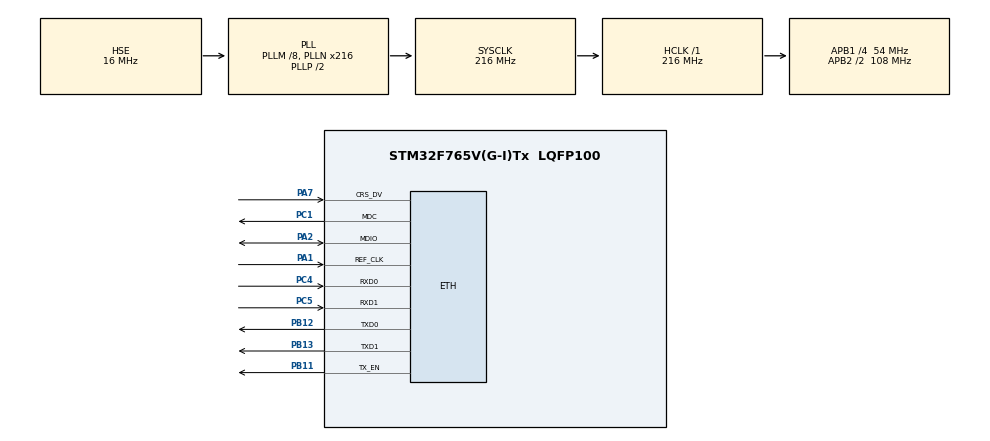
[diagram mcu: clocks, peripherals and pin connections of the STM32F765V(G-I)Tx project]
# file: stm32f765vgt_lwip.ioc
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ETH.ETH_RX_DESC_CNT=0
ETH.ETH_TX_DESC_CNT=0
ETH.MediaInterface=HAL_ETH_RMII_MODE
ETH.RxMode=ETH_RXINTERRUPT_MODE
FREERTOS.Tasks01=defaultTask,0,128,StartDefaultTask,Default,NULL,Dynamic,NULL,NULL
FREERTOS.configUSE_NEWLIB_REENTRANT=1
Mcu.Family=STM32F7
Mcu.Name=STM32F765V(G-I)Tx
Mcu.Package=LQFP100
NVIC.ETH_IRQn=true\:5\:0\:false\:false\:true\:true\:false\:true\:true
NVIC.PriorityGroup=NVIC_PRIORITYGROUP_4
NVIC.TIM8_BRK_TIM12_IRQn=true\:15\:0\:false\:false\:true\:false\:false\:true\:true
NVIC.TimeBase=TIM8_BRK_TIM12_IRQn
NVIC.TimeBaseIP=TIM12
PA1.Mode=RMII
PA1.Signal=ETH_REF_CLK
PA13.Mode=Serial_Wire
PA13.Signal=SYS_JTMS-SWDIO
PA14.Mode=Serial_Wire
PA14.Signal=SYS_JTCK-SWCLK
PA2.Mode=RMII
PA2.Signal=ETH_MDIO
PA7.Mode=RMII
PA7.Signal=ETH_CRS_DV
PB11.Mode=RMII
PB11.Signal=ETH_TX_EN
PB12.Mode=RMII
PB12.Signal=ETH_TXD0
PB13.Mode=RMII
PB13.Signal=ETH_TXD1
PC1.Mode=RMII
PC1.Signal=ETH_MDC
PC4.Mode=RMII
PC4.Signal=ETH_RXD0
PC5.Mode=RMII
PC5.Signal=ETH_RXD1
PH0/OSC_IN.Mode=HSE-External-Oscillator
PH0/OSC_IN.Signal=RCC_OSC_IN
PH1/OSC_OUT.Mode=HSE-External-Oscillator
PH1/OSC_OUT.Signal=RCC_OSC_OUT
ProjectManager.HeapSize=0x200
ProjectManager.StackSize=0x400
ProjectManager.TargetToolchain=STM32CubeIDE
RCC.AHBFreq_Value=216000000
RCC.APB1CLKDivider=RCC_HCLK_DIV4
RCC.APB1Freq_Value=54000000
RCC.APB1TimFreq_Value=108000000
RCC.APB2CLKDivider=RCC_HCLK_DIV2
RCC.APB2Freq_Value=108000000
RCC.APB2TimFreq_Value=216000000
RCC.CortexFreq_Value=216000000
RCC.HCLKFreq_Value=216000000
RCC.HSE_VALUE=16000000
RCC.HSI_VALUE=16000000
RCC.LSE_VALUE=32768
RCC.PLLM=8
RCC.PLLN=216
RCC.PLLSourceVirtual=RCC_PLLSOURCE_HSE
RCC.SYSCLKFreq_VALUE=216000000
RCC.SYSCLKSource=RCC_SYSCLKSOURCE_PLLCLK
RCC.USBFreq_Value=216000000
RCC.VCOOutputFreq_Value=432000000
VP_FREERTOS_VS_CMSIS_V1.Mode=CMSIS_V1
VP_SYS_VS_tim12.Mode=TIM12
board=custom

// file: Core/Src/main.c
/* USER CODE BEGIN Header */
/**
  ******************************************************************************
  * @file           : main.c
  * @brief          : Main program body
  ******************************************************************************
  * @attention
  *
  * Copyright (c) 2023 STMicroelectronics.
  * All rights reserved.
  *
  * This software is licensed under terms that can be found in the LICENSE file
  * in the root directory of this software component.
  * If no LICENSE file comes with this software, it is provided AS-IS.
  *
  ******************************************************************************
  */
/* USER CODE END Header */
#include "main.h"
#include "cmsis_os.h"
#include "eth.h"
#include "gpio.h"

void SystemClock_Config(void);
void MX_FREERTOS_Init(void);

int main(void)
{

  /* MCU Configuration--------------------------------------------------------*/

  /* Reset of all peripherals, Initializes the Flash interface and the Systick. */
  HAL_Init();

  /* Configure the system clock */
  SystemClock_Config();

  /* Initialize all configured peripherals */
  MX_GPIO_Init();
  MX_ETH_Init();

  /* Call init function for freertos objects (in freertos.c) */
  MX_FREERTOS_Init();

  /* Start scheduler */
  osKernelStart();

  /* We should never get here as control is now taken by the scheduler */
  /* Infinite loop */
  while (1)
  {

  }
}

void SystemClock_Config(void)
{
  RCC_OscInitTypeDef RCC_OscInitStruct = {0};
  RCC_ClkInitTypeDef RCC_ClkInitStruct = {0};

  /** Configure the main internal regulator output voltage
  */
  __HAL_RCC_PWR_CLK_ENABLE();
  __HAL_PWR_VOLTAGESCALING_CONFIG(PWR_REGULATOR_VOLTAGE_SCALE1);

  /** Initializes the RCC Oscillators according to the specified parameters
  * in the RCC_OscInitTypeDef structure.
  */
  RCC_OscInitStruct.OscillatorType = RCC_OSCILLATORTYPE_HSE;
  RCC_OscInitStruct.HSEState = RCC_HSE_ON;
  RCC_OscInitStruct.PLL.PLLState = RCC_PLL_ON;
  RCC_OscInitStruct.PLL.PLLSource = RCC_PLLSOURCE_HSE;
  RCC_OscInitStruct.PLL.PLLM = 8;
  RCC_OscInitStruct.PLL.PLLN = 216;
  RCC_OscInitStruct.PLL.PLLP = RCC_PLLP_DIV2;
  RCC_OscInitStruct.PLL.PLLQ = 2;
  RCC_OscInitStruct.PLL.PLLR = 2;
  if (HAL_RCC_OscConfig(&RCC_OscInitStruct) != HAL_OK)
  {
    Error_Handler();
  }

  /** Activate the Over-Drive mode
  */
  if (HAL_PWREx_EnableOverDrive() != HAL_OK)
  {
    Error_Handler();
  }

  /** Initializes the CPU, AHB and APB buses clocks
  */
  RCC_ClkInitStruct.ClockType = RCC_CLOCKTYPE_HCLK|RCC_CLOCKTYPE_SYSCLK
                              |RCC_CLOCKTYPE_PCLK1|RCC_CLOCKTYPE_PCLK2;
  RCC_ClkInitStruct.SYSCLKSource = RCC_SYSCLKSOURCE_PLLCLK;
  RCC_ClkInitStruct.AHBCLKDivider = RCC_SYSCLK_DIV1;
  RCC_ClkInitStruct.APB1CLKDivider = RCC_HCLK_DIV4;
  RCC_ClkInitStruct.APB2CLKDivider = RCC_HCLK_DIV2;

  if (HAL_RCC_ClockConfig(&RCC_ClkInitStruct, FLASH_LATENCY_7) != HAL_OK)
  {
    Error_Handler();
  }
}

void HAL_TIM_PeriodElapsedCallback(TIM_HandleTypeDef *htim)
{
  if (htim->Instance == TIM12) {
    HAL_IncTick();
  }
}

void Error_Handler(void)
{
  __disable_irq();
  while (1)
  {
  }
}

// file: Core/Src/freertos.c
/* USER CODE BEGIN Header */
/**
  ******************************************************************************
  * File Name          : freertos.c
  * Description        : Code for freertos applications
  ******************************************************************************
  * @attention
  *
  * Copyright (c) 2023 STMicroelectronics.
  * All rights reserved.
  *
  * This software is licensed under terms that can be found in the LICENSE file
  * in the root directory of this software component.
  * If no LICENSE file comes with this software, it is provided AS-IS.
  *
  ******************************************************************************
  */
/* USER CODE END Header */

#include "FreeRTOS.h"
#include "task.h"
#include "main.h"
#include "cmsis_os.h"

/* USER CODE BEGIN Includes */
#include "tcp_os.h"
/* USER CODE END Includes */

osThreadId defaultTaskHandle;

void StartDefaultTask(void const * argument);

void MX_FREERTOS_Init(void); /* (MISRA C 2004 rule 8.1) */

/* GetIdleTaskMemory prototype (linked to static allocation support) */
void vApplicationGetIdleTaskMemory( StaticTask_t **ppxIdleTaskTCBBuffer, StackType_t **ppxIdleTaskStackBuffer, uint32_t *pulIdleTaskStackSize );

/* USER CODE BEGIN GET_IDLE_TASK_MEMORY */
static StaticTask_t xIdleTaskTCBBuffer;
static StackType_t xIdleStack[configMINIMAL_STACK_SIZE];

void vApplicationGetIdleTaskMemory( StaticTask_t **ppxIdleTaskTCBBuffer, StackType_t **ppxIdleTaskStackBuffer, uint32_t *pulIdleTaskStackSize )
{
  *ppxIdleTaskTCBBuffer = &xIdleTaskTCBBuffer;
  *ppxIdleTaskStackBuffer = &xIdleStack[0];
  *pulIdleTaskStackSize = configMINIMAL_STACK_SIZE;
  /* place for user code */
}
/* USER CODE END GET_IDLE_TASK_MEMORY */

void MX_FREERTOS_Init(void) {

  /* Create the thread(s) */
  /* definition and creation of defaultTask */
  osThreadDef(defaultTask, StartDefaultTask, osPriorityNormal, 0, 128);
  defaultTaskHandle = osThreadCreate(osThread(defaultTask), NULL);

}

void StartDefaultTask(void const * argument)
{
  /* USER CODE BEGIN StartDefaultTask */
//  tcpecho_init();
  /* Infinite loop */
  for(;;)
  {
    osDelay(1);
  }
  /* USER CODE END StartDefaultTask */
}
